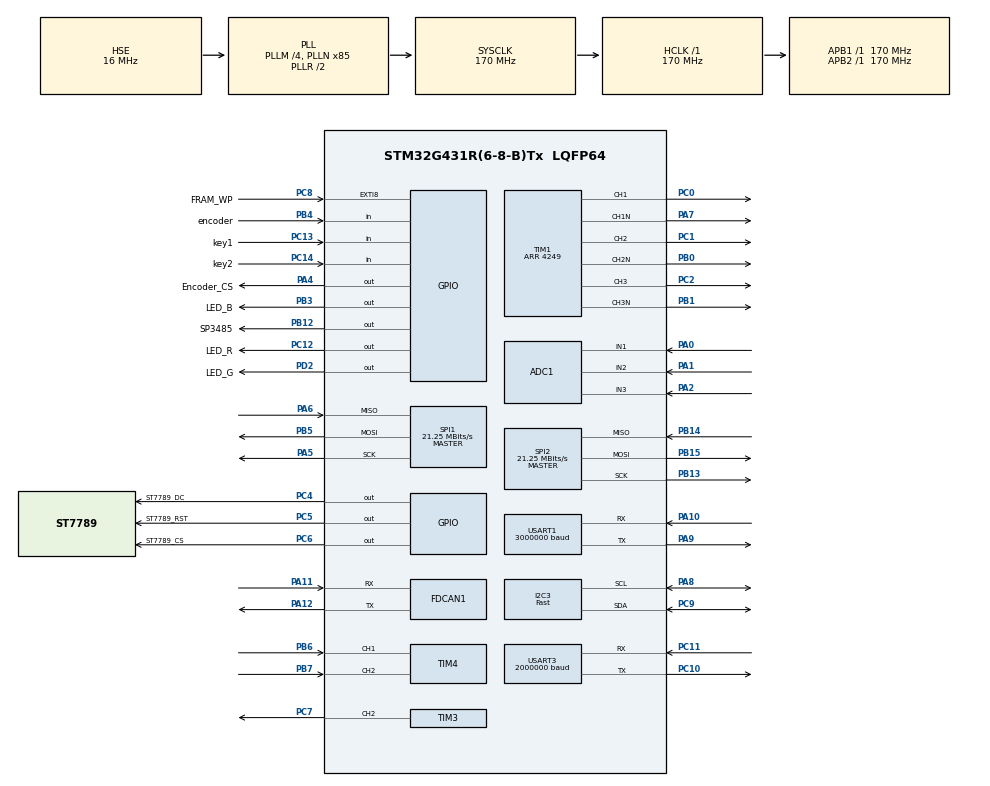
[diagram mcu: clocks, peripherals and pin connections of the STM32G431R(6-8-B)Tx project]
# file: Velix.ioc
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ADC1.Channel-1\#ChannelRegularConversion=ADC_CHANNEL_3
ADC1.ContinuousConvMode=ENABLE
ADC1.DMAContinuousRequests=ENABLE
ADC1.EnableInjectedConversion=ENABLE
ADC1.ExternalTrigInjecConv=ADC_EXTERNALTRIGINJEC_T1_CC4
ADC1.ExternalTrigInjecConvEdge=ADC_EXTERNALTRIGINJECCONV_EDGE_RISING
ADC1.InjNumberOfConversion=2
ADC1.InjectedChannel-2\#ChannelInjectedConversion=ADC_CHANNEL_1
ADC1.InjectedChannel-3\#ChannelInjectedConversion=ADC_CHANNEL_2
ADC1.InjectedOffsetNumber-2\#ChannelInjectedConversion=ADC_OFFSET_NONE
ADC1.InjectedOffsetNumber-3\#ChannelInjectedConversion=ADC_OFFSET_NONE
ADC1.InjectedRank-2\#ChannelInjectedConversion=1
ADC1.InjectedRank-3\#ChannelInjectedConversion=2
ADC1.InjectedSamplingTime-2\#ChannelInjectedConversion=ADC_SAMPLETIME_6CYCLES_5
ADC1.InjectedSamplingTime-3\#ChannelInjectedConversion=ADC_SAMPLETIME_6CYCLES_5
ADC1.NbrOfConversion=1
ADC1.NbrOfConversionFlag=1
ADC1.OffsetNumber-1\#ChannelRegularConversion=ADC_OFFSET_NONE
ADC1.Rank-1\#ChannelRegularConversion=1
ADC1.Rank1_Channel=ADC_CHANNEL_1
ADC1.Rank2_Channel=ADC_CHANNEL_2
ADC1.Rank3_Channel=ADC_CHANNEL_3
ADC1.SamplingTime-1\#ChannelRegularConversion=ADC_SAMPLETIME_12CYCLES_5
ADC1.master=1
Dma.ADC1.5.Direction=DMA_PERIPH_TO_MEMORY
Dma.ADC1.5.EventEnable=DISABLE
Dma.ADC1.5.Instance=DMA1_Channel6
Dma.ADC1.5.MemDataAlignment=DMA_MDATAALIGN_HALFWORD
Dma.ADC1.5.MemInc=DMA_MINC_ENABLE
Dma.ADC1.5.Mode=DMA_CIRCULAR
Dma.ADC1.5.PeriphDataAlignment=DMA_PDATAALIGN_HALFWORD
Dma.ADC1.5.PeriphInc=DMA_PINC_DISABLE
Dma.ADC1.5.Polarity=HAL_DMAMUX_REQ_GEN_RISING
Dma.ADC1.5.Priority=DMA_PRIORITY_LOW
Dma.ADC1.5.RequestNumber=1
Dma.ADC1.5.SignalID=NONE
Dma.ADC1.5.SyncEnable=DISABLE
Dma.ADC1.5.SyncPolarity=HAL_DMAMUX_SYNC_NO_EVENT
Dma.ADC1.5.SyncRequestNumber=1
Dma.ADC1.5.SyncSignalID=NONE
Dma.Request0=USART3_RX
Dma.Request1=USART3_TX
Dma.Request2=USART1_RX
Dma.Request3=USART1_TX
Dma.Request4=SPI2_TX
Dma.Request5=ADC1
Dma.SPI2_TX.4.Direction=DMA_MEMORY_TO_PERIPH
Dma.SPI2_TX.4.EventEnable=DISABLE
Dma.SPI2_TX.4.Instance=DMA1_Channel5
Dma.SPI2_TX.4.MemDataAlignment=DMA_MDATAALIGN_BYTE
Dma.SPI2_TX.4.MemInc=DMA_MINC_ENABLE
Dma.SPI2_TX.4.Mode=DMA_NORMAL
Dma.SPI2_TX.4.PeriphDataAlignment=DMA_PDATAALIGN_BYTE
Dma.SPI2_TX.4.PeriphInc=DMA_PINC_DISABLE
Dma.SPI2_TX.4.Polarity=HAL_DMAMUX_REQ_GEN_RISING
Dma.SPI2_TX.4.Priority=DMA_PRIORITY_LOW
Dma.SPI2_TX.4.RequestNumber=1
Dma.SPI2_TX.4.SignalID=NONE
Dma.SPI2_TX.4.SyncEnable=DISABLE
Dma.SPI2_TX.4.SyncPolarity=HAL_DMAMUX_SYNC_NO_EVENT
Dma.SPI2_TX.4.SyncRequestNumber=1
Dma.SPI2_TX.4.SyncSignalID=NONE
Dma.USART1_RX.2.Direction=DMA_PERIPH_TO_MEMORY
Dma.USART1_RX.2.EventEnable=DISABLE
Dma.USART1_RX.2.Instance=DMA1_Channel3
Dma.USART1_RX.2.MemDataAlignment=DMA_MDATAALIGN_BYTE
Dma.USART1_RX.2.MemInc=DMA_MINC_ENABLE
Dma.USART1_RX.2.Mode=DMA_CIRCULAR
Dma.USART1_RX.2.PeriphDataAlignment=DMA_PDATAALIGN_BYTE
Dma.USART1_RX.2.PeriphInc=DMA_PINC_DISABLE
Dma.USART1_RX.2.Polarity=HAL_DMAMUX_REQ_GEN_RISING
Dma.USART1_RX.2.Priority=DMA_PRIORITY_LOW
Dma.USART1_RX.2.RequestNumber=1
Dma.USART1_RX.2.SignalID=NONE
Dma.USART1_RX.2.SyncEnable=DISABLE
Dma.USART1_RX.2.SyncPolarity=HAL_DMAMUX_SYNC_NO_EVENT
Dma.USART1_RX.2.SyncRequestNumber=1
Dma.USART1_RX.2.SyncSignalID=NONE
Dma.USART1_TX.3.Direction=DMA_MEMORY_TO_PERIPH
Dma.USART1_TX.3.EventEnable=DISABLE
Dma.USART1_TX.3.Instance=DMA1_Channel4
Dma.USART1_TX.3.MemDataAlignment=DMA_MDATAALIGN_BYTE
Dma.USART1_TX.3.MemInc=DMA_MINC_ENABLE
Dma.USART1_TX.3.Mode=DMA_NORMAL
Dma.USART1_TX.3.PeriphDataAlignment=DMA_PDATAALIGN_BYTE
Dma.USART1_TX.3.PeriphInc=DMA_PINC_DISABLE
Dma.USART1_TX.3.Polarity=HAL_DMAMUX_REQ_GEN_RISING
Dma.USART1_TX.3.Priority=DMA_PRIORITY_LOW
Dma.USART1_TX.3.RequestNumber=1
Dma.USART1_TX.3.SignalID=NONE
Dma.USART1_TX.3.SyncEnable=DISABLE
Dma.USART1_TX.3.SyncPolarity=HAL_DMAMUX_SYNC_NO_EVENT
Dma.USART1_TX.3.SyncRequestNumber=1
Dma.USART1_TX.3.SyncSignalID=NONE
Dma.USART3_RX.0.Direction=DMA_PERIPH_TO_MEMORY
Dma.USART3_RX.0.EventEnable=DISABLE
Dma.USART3_RX.0.Instance=DMA1_Channel1
Dma.USART3_RX.0.MemDataAlignment=DMA_MDATAALIGN_BYTE
Dma.USART3_RX.0.MemInc=DMA_MINC_ENABLE
Dma.USART3_RX.0.Mode=DMA_CIRCULAR
Dma.USART3_RX.0.PeriphDataAlignment=DMA_PDATAALIGN_BYTE
Dma.USART3_RX.0.PeriphInc=DMA_PINC_DISABLE
Dma.USART3_RX.0.Polarity=HAL_DMAMUX_REQ_GEN_RISING
Dma.USART3_RX.0.Priority=DMA_PRIORITY_LOW
Dma.USART3_RX.0.RequestNumber=1
Dma.USART3_RX.0.SignalID=NONE
Dma.USART3_RX.0.SyncEnable=DISABLE
Dma.USART3_RX.0.SyncPolarity=HAL_DMAMUX_SYNC_NO_EVENT
Dma.USART3_RX.0.SyncRequestNumber=1
Dma.USART3_RX.0.SyncSignalID=NONE
Dma.USART3_TX.1.Direction=DMA_MEMORY_TO_PERIPH
Dma.USART3_TX.1.EventEnable=DISABLE
Dma.USART3_TX.1.Instance=DMA1_Channel2
Dma.USART3_TX.1.MemDataAlignment=DMA_MDATAALIGN_BYTE
Dma.USART3_TX.1.MemInc=DMA_MINC_ENABLE
Dma.USART3_TX.1.Mode=DMA_NORMAL
Dma.USART3_TX.1.PeriphDataAlignment=DMA_PDATAALIGN_BYTE
Dma.USART3_TX.1.PeriphInc=DMA_PINC_DISABLE
Dma.USART3_TX.1.Polarity=HAL_DMAMUX_REQ_GEN_RISING
Dma.USART3_TX.1.Priority=DMA_PRIORITY_LOW
Dma.USART3_TX.1.RequestNumber=1
Dma.USART3_TX.1.SignalID=NONE
Dma.USART3_TX.1.SyncEnable=DISABLE
Dma.USART3_TX.1.SyncPolarity=HAL_DMAMUX_SYNC_NO_EVENT
Dma.USART3_TX.1.SyncRequestNumber=1
Dma.USART3_TX.1.SyncSignalID=NONE
FDCAN1.CalculateBaudRateNominal=3541666
FDCAN1.CalculateTimeBitNominal=282
FDCAN1.CalculateTimeQuantumNominal=94.11764705882354
FDCAN1.FrameFormat=FDCAN_FRAME_CLASSIC
I2C3.I2C_Speed_Mode=I2C_Fast
I2C3.Timing=0x40621236
Mcu.Family=STM32G4
Mcu.Name=STM32G431R(6-8-B)Tx
Mcu.Package=LQFP64
NVIC.ADC1_2_IRQn=true\:0\:0\:false\:false\:true\:true\:true\:true
NVIC.DMA1_Channel1_IRQn=true\:0\:0\:false\:false\:true\:false\:true\:true
NVIC.DMA1_Channel2_IRQn=true\:0\:0\:false\:false\:true\:false\:true\:true
NVIC.DMA1_Channel3_IRQn=true\:0\:0\:false\:false\:true\:false\:true\:true
NVIC.DMA1_Channel4_IRQn=true\:0\:0\:false\:false\:true\:false\:true\:true
NVIC.DMA1_Channel5_IRQn=true\:0\:0\:false\:false\:true\:false\:true\:true
NVIC.DMA1_Channel6_IRQn=true\:0\:0\:false\:false\:true\:false\:true\:true
NVIC.PriorityGroup=NVIC_PRIORITYGROUP_4
NVIC.TIM2_IRQn=true\:1\:0\:true\:false\:true\:true\:true\:true
NVIC.USART1_IRQn=true\:0\:0\:false\:false\:true\:true\:true\:true
NVIC.USART3_IRQn=true\:1\:0\:true\:false\:true\:true\:true\:true
PA0.Mode=IN1-Single-Ended
PA0.Signal=ADC1_IN1
PA1.Mode=IN2-Single-Ended
PA1.Signal=ADC1_IN2
PA10.Mode=Asynchronous
PA10.Signal=USART1_RX
PA11.Mode=FDCAN_Activate
PA11.Signal=FDCAN1_RX
PA12.Mode=FDCAN_Activate
PA12.Signal=FDCAN1_TX
PA13.Mode=Serial_Wire
PA13.Signal=SYS_JTMS-SWDIO
PA14.Mode=Serial_Wire
PA14.Signal=SYS_JTCK-SWCLK
PA2.Mode=IN3-Single-Ended
PA2.Signal=ADC1_IN3
PA4.GPIO_Label=Encoder_CS
PA4.GPIO_Speed=GPIO_SPEED_FREQ_VERY_HIGH
PA4.PinState=GPIO_PIN_SET
PA4.Signal=GPIO_Output
PA5.GPIO_Speed=GPIO_SPEED_FREQ_VERY_HIGH
PA5.Mode=Full_Duplex_Master
PA5.Signal=SPI1_SCK
PA6.GPIO_Speed=GPIO_SPEED_FREQ_VERY_HIGH
PA6.Mode=Full_Duplex_Master
PA6.Signal=SPI1_MISO
PA7.Mode=PWM Generation1 CH1 CH1N
PA7.Signal=TIM1_CH1N
PA8.Mode=I2C
PA8.Signal=I2C3_SCL
PA9.Mode=Asynchronous
PA9.Signal=USART1_TX
PB0.Mode=PWM Generation2 CH2 CH2N
PB0.Signal=TIM1_CH2N
PB1.Mode=PWM Generation3 CH3 CH3N
PB1.Signal=TIM1_CH3N
PB12.GPIO_Label=SP3485
PB12.Signal=GPIO_Output
PB13.GPIO_Speed=GPIO_SPEED_FREQ_VERY_HIGH
PB13.Mode=Full_Duplex_Master
PB13.Signal=SPI2_SCK
PB14.GPIO_Speed=GPIO_SPEED_FREQ_VERY_HIGH
PB14.Mode=Full_Duplex_Master
PB14.Signal=SPI2_MISO
PB15.GPIO_Speed=GPIO_SPEED_FREQ_VERY_HIGH
PB15.Mode=Full_Duplex_Master
PB15.Signal=SPI2_MOSI
PB3.GPIO_Label=LED_B
PB3.Signal=GPIO_Output
PB4.GPIO_Label=encoder
PB4.Signal=GPIO_Input
PB5.GPIO_Speed=GPIO_SPEED_FREQ_VERY_HIGH
PB5.Mode=Full_Duplex_Master
PB5.Signal=SPI1_MOSI
PB6.Signal=S_TIM4_CH1
PB7.Signal=S_TIM4_CH2
PC0.Signal=S_TIM1_CH1
PC1.Signal=S_TIM1_CH2
PC10.Mode=Asynchronous
PC10.Signal=USART3_TX
PC11.Mode=Asynchronous
PC11.Signal=USART3_RX
PC12.GPIO_Label=LED_R
PC12.Signal=GPIO_Output
PC13.GPIO_Label=key1
PC13.Signal=GPIO_Input
PC14-OSC32_IN.GPIO_Label=key2
PC14-OSC32_IN.Signal=GPIO_Input
PC2.Signal=S_TIM1_CH3
PC4.GPIO_Label=ST7789_DC
PC4.GPIO_Speed=GPIO_SPEED_FREQ_VERY_HIGH
PC4.PinState=GPIO_PIN_RESET
PC4.Signal=GPIO_Output
PC5.GPIO_Label=ST7789_RST
PC5.GPIO_Speed=GPIO_SPEED_FREQ_VERY_HIGH
PC5.Signal=GPIO_Output
PC6.GPIO_Label=ST7789_CS
PC6.GPIO_Speed=GPIO_SPEED_FREQ_VERY_HIGH
PC6.PinState=GPIO_PIN_SET
PC6.Signal=GPIO_Output
PC7.Signal=S_TIM3_CH2
PC8.GPIO_Label=FRAM_WP
PC8.Signal=GPXTI8
PC9.Mode=I2C
PC9.Signal=I2C3_SDA
PD2.GPIO_Label=LED_G
PD2.Signal=GPIO_Output
PF0-OSC_IN.Mode=HSE-External-Oscillator
PF0-OSC_IN.Signal=RCC_OSC_IN
PF1-OSC_OUT.Mode=HSE-External-Oscillator
PF1-OSC_OUT.Signal=RCC_OSC_OUT
ProjectManager.HeapSize=0x200
ProjectManager.StackSize=0x400
ProjectManager.TargetToolchain=CMake
RCC.ADC12Freq_Value=170000000
RCC.AHBFreq_Value=170000000
RCC.APB1Freq_Value=170000000
RCC.APB1TimFreq_Value=170000000
RCC.APB2Freq_Value=170000000
RCC.APB2TimFreq_Value=170000000
RCC.CortexFreq_Value=170000000
RCC.EXTERNAL_CLOCK_VALUE=12288000
RCC.HCLKFreq_Value=170000000
RCC.HSE_VALUE=16000000
RCC.HSI48_VALUE=48000000
RCC.HSI_VALUE=16000000
RCC.LSE_VALUE=32768
RCC.PLLM=RCC_PLLM_DIV4
RCC.PLLN=85
RCC.PLLSourceVirtual=RCC_PLLSOURCE_HSE
RCC.SYSCLKFreq_VALUE=170000000
RCC.SYSCLKSource=RCC_SYSCLKSOURCE_PLLCLK
RCC.USBFreq_Value=170000000
RCC.VCOOutputFreq_Value=340000000
SH.S_TIM1_CH1.0=TIM1_CH1,PWM Generation1 CH1 CH1N
SH.S_TIM1_CH2.0=TIM1_CH2,PWM Generation2 CH2 CH2N
SH.S_TIM1_CH3.0=TIM1_CH3,PWM Generation3 CH3 CH3N
SH.S_TIM3_CH2.0=TIM3_CH2,PWM Generation2 CH2
SH.S_TIM4_CH1.0=TIM4_CH1,Encoder_Interface
SH.S_TIM4_CH2.0=TIM4_CH2,Encoder_Interface
SPI1.BaudRatePrescaler=SPI_BAUDRATEPRESCALER_8
SPI1.CLKPhase=SPI_PHASE_2EDGE
SPI1.CalculateBaudRate=21.25 MBits/s
SPI1.DataSize=SPI_DATASIZE_16BIT
SPI1.Direction=SPI_DIRECTION_2LINES
SPI1.Mode=SPI_MODE_MASTER
SPI1.VirtualType=VM_MASTER
SPI2.BaudRatePrescaler=SPI_BAUDRATEPRESCALER_8
SPI2.CalculateBaudRate=21.25 MBits/s
SPI2.DataSize=SPI_DATASIZE_8BIT
SPI2.Direction=SPI_DIRECTION_2LINES
SPI2.Mode=SPI_MODE_MASTER
SPI2.VirtualType=VM_MASTER
STMicroelectronics.X-CUBE-ALGOBUILD.1.4.0.LibraryCcDSPOoLibraryJjDSPOoLibrary=true
TIM1.Channel-PWM\ Generation1\ CH1\ CH1N=TIM_CHANNEL_1
TIM1.Channel-PWM\ Generation2\ CH2\ CH2N=TIM_CHANNEL_2
TIM1.Channel-PWM\ Generation3\ CH3\ CH3N=TIM_CHANNEL_3
TIM1.Channel-PWM\ Generation4\ No\ Output=TIM_CHANNEL_4
TIM1.CounterMode=TIM_COUNTERMODE_CENTERALIGNED1
TIM1.DeadTime=50
TIM1.PeriodNoDither=4249
TIM2.PeriodNoDither=1000-1
TIM2.Prescaler=170-1
TIM3.Channel-PWM\ Generation2\ CH2=TIM_CHANNEL_2
TIM4.EncoderMode=TIM_ENCODERMODE_TI12
USART1.BaudRate=3000000
USART1.VirtualMode-Asynchronous=VM_ASYNC
USART3.BaudRate=2000000
USART3.VirtualMode-Asynchronous=VM_ASYNC
VP_CORDIC_VS_CORDIC.Mode=CORDIC_Activate
VP_STMicroelectronics.X-CUBE-ALGOBUILD_VS_DSPOoLibraryJjLibrary_1.4.0_1.4.0.Mode=DSPOoLibraryJjLibrary
VP_SYS_VS_DBSignals.Mode=DisableDeadBatterySignals
VP_TIM1_VS_ClockSourceINT.Mode=Internal
VP_TIM1_VS_no_output4.Mode=PWM Generation4 No Output
VP_TIM2_VS_ClockSourceINT.Mode=Internal
board=custom

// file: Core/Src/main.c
/* USER CODE BEGIN Header */
/**
  ******************************************************************************
  * @file           : main.c
  * @brief          : Main program body
  ******************************************************************************
  * @attention
  *
  * Copyright (c) 2026 STMicroelectronics.
  * All rights reserved.
  *
  * This software is licensed under terms that can be found in the LICENSE file
  * in the root directory of this software component.
  * If no LICENSE file comes with this software, it is provided AS-IS.
  *
  ******************************************************************************
  */
/* USER CODE END Header */
#include "main.h"
#include "adc.h"
#include "cordic.h"
#include "dma.h"
#include "fdcan.h"
#include "i2c.h"
#include "spi.h"
#include "tim.h"
#include "usart.h"
#include "gpio.h"

/* USER CODE BEGIN Includes */
#include "global.h"
#include "st7789.h"
/* USER CODE END Includes */

void SystemClock_Config(void);

int main(void)
{

  /* MCU Configuration--------------------------------------------------------*/

  /* Reset of all peripherals, Initializes the Flash interface and the Systick. */
  HAL_Init();

  /* Configure the system clock */
  SystemClock_Config();

  /* Initialize all configured peripherals */
  MX_GPIO_Init();
  MX_DMA_Init();
  MX_TIM1_Init();
  MX_USART1_UART_Init();
  MX_ADC1_Init();
  MX_SPI1_Init();
  MX_USART3_UART_Init();
  MX_TIM2_Init();
  MX_CORDIC_Init();
  MX_FDCAN1_Init();
  MX_SPI2_Init();
  MX_TIM4_Init();
  MX_I2C3_Init();
  MX_TIM3_Init();
  /* USER CODE BEGIN 2 */
  HAL_TIM_PWM_Start(&htim3, TIM_CHANNEL_2);
  __HAL_TIM_SET_COMPARE(&htim3, TIM_CHANNEL_2, 60000);
  ST7789_Init();
  //ST7789_Test();
  //ST7789_Test_1();
  System_Init();
  /* USER CODE END 2 */

  /* Infinite loop */
  /* USER CODE BEGIN WHILE */
  while (1)
  {
    System_Loop();
    /* USER CODE END WHILE */

  }
}

void SystemClock_Config(void)
{
  RCC_OscInitTypeDef RCC_OscInitStruct = {0};
  RCC_ClkInitTypeDef RCC_ClkInitStruct = {0};

  /** Configure the main internal regulator output voltage
  */
  HAL_PWREx_ControlVoltageScaling(PWR_REGULATOR_VOLTAGE_SCALE1_BOOST);

  /** Initializes the RCC Oscillators according to the specified parameters
  * in the RCC_OscInitTypeDef structure.
  */
  RCC_OscInitStruct.OscillatorType = RCC_OSCILLATORTYPE_HSE;
  RCC_OscInitStruct.HSEState = RCC_HSE_ON;
  RCC_OscInitStruct.PLL.PLLState = RCC_PLL_ON;
  RCC_OscInitStruct.PLL.PLLSource = RCC_PLLSOURCE_HSE;
  RCC_OscInitStruct.PLL.PLLM = RCC_PLLM_DIV4;
  RCC_OscInitStruct.PLL.PLLN = 85;
  RCC_OscInitStruct.PLL.PLLP = RCC_PLLP_DIV2;
  RCC_OscInitStruct.PLL.PLLQ = RCC_PLLQ_DIV2;
  RCC_OscInitStruct.PLL.PLLR = RCC_PLLR_DIV2;
  if (HAL_RCC_OscConfig(&RCC_OscInitStruct) != HAL_OK)
  {
    Error_Handler();
  }

  /** Initializes the CPU, AHB and APB buses clocks
  */
  RCC_ClkInitStruct.ClockType = RCC_CLOCKTYPE_HCLK|RCC_CLOCKTYPE_SYSCLK
                              |RCC_CLOCKTYPE_PCLK1|RCC_CLOCKTYPE_PCLK2;
  RCC_ClkInitStruct.SYSCLKSource = RCC_SYSCLKSOURCE_PLLCLK;
  RCC_ClkInitStruct.AHBCLKDivider = RCC_SYSCLK_DIV1;
  RCC_ClkInitStruct.APB1CLKDivider = RCC_HCLK_DIV1;
  RCC_ClkInitStruct.APB2CLKDivider = RCC_HCLK_DIV1;

  if (HAL_RCC_ClockConfig(&RCC_ClkInitStruct, FLASH_LATENCY_4) != HAL_OK)
  {
    Error_Handler();
  }
}

void Error_Handler(void)
{
  /* USER CODE BEGIN Error_Handler_Debug */
  /* User can add his own implementation to report the HAL error return state */
  __disable_irq();
  while (1)
  {
    HAL_GPIO_WritePin(LED_R_GPIO_Port, LED_R_Pin, GPIO_PIN_RESET);
    HAL_GPIO_WritePin(LED_G_GPIO_Port, LED_G_Pin, GPIO_PIN_SET);
    HAL_GPIO_WritePin(LED_B_GPIO_Port, LED_B_Pin, GPIO_PIN_SET);
  }
  /* USER CODE END Error_Handler_Debug */
}
